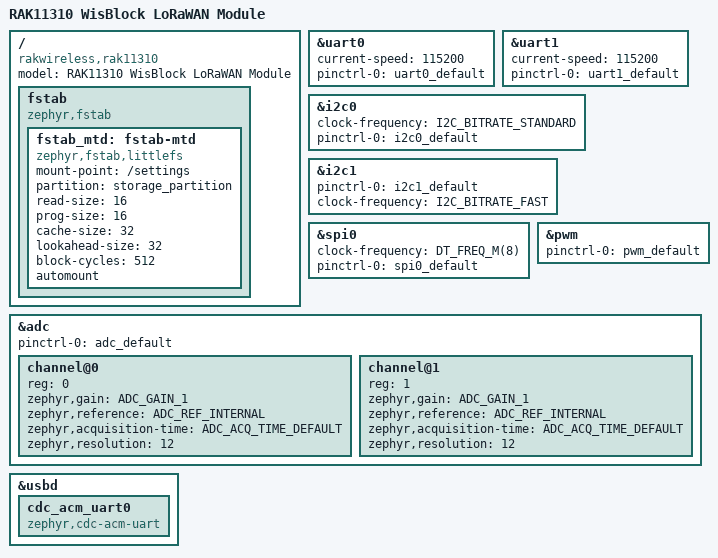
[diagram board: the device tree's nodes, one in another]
/*
 * SPDX-License-Identifier: Apache-2.0
 * Copyright (c) 2026 RAKwireless Technology Limited
 */

/dts-v1/;
#include <rakwireless/rak11300.dtsi>
#include "rak11310-pinctrl.dtsi"

/ {
	model = "RAK11310 WisBlock LoRaWAN Module";
        compatible = "rakwireless,rak11310";


	fstab {
		compatible = "zephyr,fstab";

		fstab_mtd: fstab-mtd {
			compatible = "zephyr,fstab,littlefs";
			mount-point = "/settings";
			partition = <&storage_partition>;
			read-size = <16>;
			prog-size = <16>;
			cache-size = <32>;
			lookahead-size = <32>;
			block-cycles = <512>;
			automount;
		};
	};
};

&uart0 {
	current-speed = <115200>;
	pinctrl-0 = <&uart0_default>;
	pinctrl-names = "default";
};

&uart1 {
	current-speed = <115200>;
	pinctrl-0 = <&uart1_default>;
	pinctrl-names = "default";
};

&i2c0 {
	clock-frequency = <I2C_BITRATE_STANDARD>;
	pinctrl-0 = <&i2c0_default>;
	pinctrl-names = "default";
};

&i2c1 {
	pinctrl-0 = <&i2c1_default>;
	pinctrl-names = "default";
	clock-frequency = <I2C_BITRATE_FAST>;
};

&spi0 {
	clock-frequency = <DT_FREQ_M(8)>;
	pinctrl-0 = <&spi0_default>;
	pinctrl-names = "default";

};

&pwm {
	status = "okay";
	pinctrl-0 = <&pwm_default>;
	pinctrl-names = "default";
};

&adc {
	status = "okay";
	pinctrl-0 = <&adc_default>;
	pinctrl-names = "default";
	#address-cells = <1>;
	#size-cells = <0>;

	channel@0 {
		reg = <0>;
		zephyr,gain = "ADC_GAIN_1";
		zephyr,reference = "ADC_REF_INTERNAL";
		zephyr,acquisition-time = <ADC_ACQ_TIME_DEFAULT>;
		zephyr,resolution = <12>;
	};

	channel@1 {
		reg = <1>;
		zephyr,gain = "ADC_GAIN_1";
		zephyr,reference = "ADC_REF_INTERNAL";
		zephyr,acquisition-time = <ADC_ACQ_TIME_DEFAULT>;
		zephyr,resolution = <12>;
	};
};

zephyr_udc0: &usbd {
	status = "okay";

	cdc_acm_uart0: cdc_acm_uart0 {
		status = "okay";
		compatible = "zephyr,cdc-acm-uart";
	};
};

#include "wisblock.dtsi"
